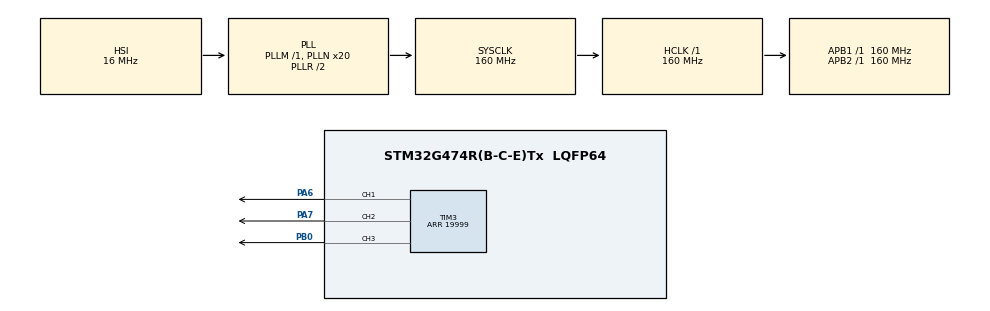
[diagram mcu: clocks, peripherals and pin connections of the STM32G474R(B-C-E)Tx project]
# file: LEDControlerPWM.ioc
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Mcu.Family=STM32G4
Mcu.Name=STM32G474R(B-C-E)Tx
Mcu.Package=LQFP64
NVIC.PriorityGroup=NVIC_PRIORITYGROUP_4
PA13.Mode=Serial_Wire
PA13.Signal=SYS_JTMS-SWDIO
PA14.Mode=Serial_Wire
PA14.Signal=SYS_JTCK-SWCLK
PA6.Signal=S_TIM3_CH1
PA7.Signal=S_TIM3_CH2
PB0.Signal=S_TIM3_CH3
ProjectManager.HeapSize=0x200
ProjectManager.StackSize=0x400
ProjectManager.TargetToolchain=STM32CubeIDE
RCC.ADC12Freq_Value=160000000
RCC.ADC345Freq_Value=160000000
RCC.AHBFreq_Value=160000000
RCC.APB1Freq_Value=160000000
RCC.APB1TimFreq_Value=160000000
RCC.APB2Freq_Value=160000000
RCC.APB2TimFreq_Value=160000000
RCC.CortexFreq_Value=160000000
RCC.EXTERNAL_CLOCK_VALUE=12288000
RCC.HCLKFreq_Value=160000000
RCC.HSE_VALUE=8000000
RCC.HSI48_VALUE=48000000
RCC.HSI_VALUE=16000000
RCC.LSE_VALUE=32768
RCC.PLLN=20
RCC.SYSCLKFreq_VALUE=160000000
RCC.SYSCLKSource=RCC_SYSCLKSOURCE_PLLCLK
RCC.USBFreq_Value=160000000
RCC.VCOOutputFreq_Value=320000000
SH.S_TIM3_CH1.0=TIM3_CH1,PWM Generation1 CH1
SH.S_TIM3_CH2.0=TIM3_CH2,PWM Generation2 CH2
SH.S_TIM3_CH3.0=TIM3_CH3,PWM Generation3 CH3
TIM3.Channel-PWM\ Generation1\ CH1=TIM_CHANNEL_1
TIM3.Channel-PWM\ Generation2\ CH2=TIM_CHANNEL_2
TIM3.Channel-PWM\ Generation3\ CH3=TIM_CHANNEL_3
TIM3.OCPolarity_1=TIM_OCPOLARITY_LOW
TIM3.OCPolarity_2=TIM_OCPOLARITY_LOW
TIM3.OCPolarity_3=TIM_OCPOLARITY_LOW
TIM3.PeriodNoDither=19999
TIM3.PulseNoDither_1=400
TIM3.PulseNoDither_2=400
TIM3.PulseNoDither_3=400
VP_TIM3_VS_ClockSourceINT.Mode=Internal
board=custom

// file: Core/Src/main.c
/* USER CODE BEGIN Header */
/**
  ******************************************************************************
  * @file           : main.c
  * @brief          : Main program body
  ******************************************************************************
  * @attention
  *
  * Copyright (c) 2022 STMicroelectronics.
  * All rights reserved.
  *
  * This software is licensed under terms that can be found in the LICENSE file
  * in the root directory of this software component.
  * If no LICENSE file comes with this software, it is provided AS-IS.
  *
  ******************************************************************************
  */
/* USER CODE END Header */
#include "main.h"

/* USER CODE BEGIN Includes */
#include <math.h>
/* USER CODE END Includes */

TIM_HandleTypeDef htim3;

void SystemClock_Config(void);
static void MX_GPIO_Init(void);
static void MX_TIM3_Init(void);

/* USER CODE BEGIN 0 */
/*
 * The way my project is set up that
 * PB0 - blue LED cathode
 * PA6 - red LED cathode
 * PA7 - green LED cathode
 *
 * 5V output - anode of RGB LED
 *
 * Debugger connected to and PA14 (SWCLK) and PA13 (SWDIO)
 *
 * */

//it is an amplitude of the functions
const float A = 2.0f;
//this variable defines period of the functions
const float T = 2.0f;

//This function helps to fix
//linearity of the brightness of the led
float fix_linearity(float val)
{
	//https://en.wikipedia.org/wiki/Logistic_function
	const float L = 10000.0f;
	const float k = 0.13f;
	const float x0 = 70.0f;
	return L / (1.0f + exp(-k * (val - x0)));
}

/* USER CODE END 0 */

int main(void)
{

  /* MCU Configuration--------------------------------------------------------*/

  /* Reset of all peripherals, Initializes the Flash interface and the Systick. */
  HAL_Init();

  /* Configure the system clock */
  SystemClock_Config();

  /* Initialize all configured peripherals */
  MX_GPIO_Init();
  MX_TIM3_Init();
  /* USER CODE BEGIN 2 */

  //Initialize TIM timer for PWM
  HAL_TIM_Base_Start_IT(&htim3);
  HAL_TIM_PWM_Start(&htim3, TIM_CHANNEL_1);
  HAL_TIM_PWM_Start(&htim3, TIM_CHANNEL_2);
  HAL_TIM_PWM_Start(&htim3, TIM_CHANNEL_3);

  //define necessary variables outside of loop
  //x - will store input for functions
  //r - represents rred color
  //g - represents green color
  //b - represents blue color
  float x, r, g, b;
  /* USER CODE END 2 */

  /* Infinite loop */
  /* USER CODE BEGIN WHILE */
  while (1)
  {

	  //lets define input for the function
	  //HAL_GetTick() returns milliseconds from start of the program
	  //if we divide it by 1000 we get seconds
	  x = HAL_GetTick()/1000.0f;

	  //individual colors are defined by functions as in the desmos graph
	  //https://www.desmos.com/calculator/vbny3qbezo
	  r = A*sin((x-T/4.0f)*2*M_PI/T)+A;
	  g = A*2.0f*((x - T/2.0f)/T - floor(0.5f + (x - T/2.0f)/T)) + A;
	  b = (4.0f*A/T)*fabs(fmod(x-T/2.0f,T) - T/2.0f);

	  //it sets TIM compare registers (basically sets led value)
	  __HAL_TIM_SET_COMPARE(&htim3, TIM_CHANNEL_1, fix_linearity(r*15)*10);
	  __HAL_TIM_SET_COMPARE(&htim3, TIM_CHANNEL_2, fix_linearity(g*15)*10);
	  __HAL_TIM_SET_COMPARE(&htim3, TIM_CHANNEL_3, fix_linearity(b*15)*10);

	  //simple delay
	  HAL_Delay(10);

    /* USER CODE END WHILE */

  }
}

void SystemClock_Config(void)
{
  RCC_OscInitTypeDef RCC_OscInitStruct = {0};
  RCC_ClkInitTypeDef RCC_ClkInitStruct = {0};

  /** Configure the main internal regulator output voltage
  */
  HAL_PWREx_ControlVoltageScaling(PWR_REGULATOR_VOLTAGE_SCALE1_BOOST);

  /** Initializes the RCC Oscillators according to the specified parameters
  * in the RCC_OscInitTypeDef structure.
  */
  RCC_OscInitStruct.OscillatorType = RCC_OSCILLATORTYPE_HSI;
  RCC_OscInitStruct.HSIState = RCC_HSI_ON;
  RCC_OscInitStruct.HSICalibrationValue = RCC_HSICALIBRATION_DEFAULT;
  RCC_OscInitStruct.PLL.PLLState = RCC_PLL_ON;
  RCC_OscInitStruct.PLL.PLLSource = RCC_PLLSOURCE_HSI;
  RCC_OscInitStruct.PLL.PLLM = RCC_PLLM_DIV1;
  RCC_OscInitStruct.PLL.PLLN = 20;
  RCC_OscInitStruct.PLL.PLLP = RCC_PLLP_DIV2;
  RCC_OscInitStruct.PLL.PLLQ = RCC_PLLQ_DIV2;
  RCC_OscInitStruct.PLL.PLLR = RCC_PLLR_DIV2;
  if (HAL_RCC_OscConfig(&RCC_OscInitStruct) != HAL_OK)
  {
    Error_Handler();
  }

  /** Initializes the CPU, AHB and APB buses clocks
  */
  RCC_ClkInitStruct.ClockType = RCC_CLOCKTYPE_HCLK|RCC_CLOCKTYPE_SYSCLK
                              |RCC_CLOCKTYPE_PCLK1|RCC_CLOCKTYPE_PCLK2;
  RCC_ClkInitStruct.SYSCLKSource = RCC_SYSCLKSOURCE_PLLCLK;
  RCC_ClkInitStruct.AHBCLKDivider = RCC_SYSCLK_DIV1;
  RCC_ClkInitStruct.APB1CLKDivider = RCC_HCLK_DIV1;
  RCC_ClkInitStruct.APB2CLKDivider = RCC_HCLK_DIV1;

  if (HAL_RCC_ClockConfig(&RCC_ClkInitStruct, FLASH_LATENCY_4) != HAL_OK)
  {
    Error_Handler();
  }
}

static void MX_TIM3_Init(void)
{

  TIM_ClockConfigTypeDef sClockSourceConfig = {0};
  TIM_MasterConfigTypeDef sMasterConfig = {0};
  TIM_OC_InitTypeDef sConfigOC = {0};

  htim3.Instance = TIM3;
  htim3.Init.Prescaler = 0;
  htim3.Init.CounterMode = TIM_COUNTERMODE_UP;
  htim3.Init.Period = 19999;
  htim3.Init.ClockDivision = TIM_CLOCKDIVISION_DIV1;
  htim3.Init.AutoReloadPreload = TIM_AUTORELOAD_PRELOAD_DISABLE;
  if (HAL_TIM_Base_Init(&htim3) != HAL_OK)
  {
    Error_Handler();
  }
  sClockSourceConfig.ClockSource = TIM_CLOCKSOURCE_INTERNAL;
  if (HAL_TIM_ConfigClockSource(&htim3, &sClockSourceConfig) != HAL_OK)
  {
    Error_Handler();
  }
  if (HAL_TIM_PWM_Init(&htim3) != HAL_OK)
  {
    Error_Handler();
  }
  sMasterConfig.MasterOutputTrigger = TIM_TRGO_RESET;
  sMasterConfig.MasterSlaveMode = TIM_MASTERSLAVEMODE_DISABLE;
  if (HAL_TIMEx_MasterConfigSynchronization(&htim3, &sMasterConfig) != HAL_OK)
  {
    Error_Handler();
  }
  sConfigOC.OCMode = TIM_OCMODE_PWM1;
  sConfigOC.Pulse = 400;
  sConfigOC.OCPolarity = TIM_OCPOLARITY_LOW;
  sConfigOC.OCFastMode = TIM_OCFAST_DISABLE;
  if (HAL_TIM_PWM_ConfigChannel(&htim3, &sConfigOC, TIM_CHANNEL_1) != HAL_OK)
  {
    Error_Handler();
  }
  if (HAL_TIM_PWM_ConfigChannel(&htim3, &sConfigOC, TIM_CHANNEL_2) != HAL_OK)
  {
    Error_Handler();
  }
  if (HAL_TIM_PWM_ConfigChannel(&htim3, &sConfigOC, TIM_CHANNEL_3) != HAL_OK)
  {
    Error_Handler();
  }
  HAL_TIM_MspPostInit(&htim3);

}

static void MX_GPIO_Init(void)
{

  /* GPIO Ports Clock Enable */
  __HAL_RCC_GPIOA_CLK_ENABLE();
  __HAL_RCC_GPIOB_CLK_ENABLE();

}

void Error_Handler(void)
{
  __disable_irq();
  while (1)
  {
  }
}
